AUTOSAR XML (schema 4-2-2)
standard types defined: boolean, float32, float64, sint16, sint32, sint64, sint8, uint16, uint32, uint64, uint8, void
package /BSW/ImplementationDataTypes
  6 x impl type:
    ConstVoidPtr: category=DATA_REFERENCE, sw-pointer-target-props={target-category=VALUE, base-type=void, sw-impl-policy=CONST}
    NvM_BlockIdType: category=VALUE, base-type=uint16
    NvM_BlockRequestType: compu {0x00=NVM_READ_BLOCK, 0x01=NVM_WRITE_BLOCK, 0x02=NVM_RESTORE_BLOCK_DEFAULTS, 0x03=NVM_ERASE_NV_BLOCK, 0x04=NVM_INVALIDATE_NV_BLOCK, 0x05=NVM_READ_ALL_BLOCK, 0x06=NVM_WRITE_ALL_BLOCK}, implementation-data-type=uint8
    NvM_InitBlockRequestType: compu {0x00=NVM_INIT_READ_BLOCK, 0x01=NVM_INIT_RESTORE_BLOCK_DEFAULTS, 0x02=NVM_INIT_READ_ALL_BLOCK, 0x03=NVM_INIT_FIRST_INIT_ALL}, implementation-data-type=uint8
    NvM_RequestResultType: compu {0x00=NVM_REQ_OK, 0x01=NVM_REQ_NOT_OK, 0x02=NVM_REQ_PENDING, 0x03=NVM_REQ_INTEGRITY_FAILED, 0x04=NVM_REQ_BLOCK_SKIPPED, 0x05=NVM_REQ_NV_INVALIDATED, 0x06=NVM_REQ_CANCELED, 0x08=NVM_REQ_RESTORED_DEFAULTS}, implementation-data-type=uint8
    VoidPtr: category=DATA_REFERENCE, sw-pointer-target-props={target-category=VALUE, base-type=void}
package /BSW/PortInterfaces
  client server interface NvM_ReadAll: service-kind=NON-VOLATILE-RAM-MANAGER
    operation ReadAll: possible-error=[NvM_ReadAll/E_NOT_OK, NvM_ReadAll/E_OK]
    error E_NOT_OK: error-code=1
    error E_OK: error-code=0
  client server interface NvM_WriteAll: service-kind=NON-VOLATILE-RAM-MANAGER
    operation WriteAll: possible-error=[NvM_WriteAll/E_NOT_OK, NvM_WriteAll/E_OK]
    error E_NOT_OK: error-code=1
    error E_OK: error-code=0
package /BSW/SWCs
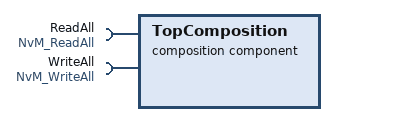
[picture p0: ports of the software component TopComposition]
  composition sw component type TopComposition
    require port ReadAll: required-interface=NvM_ReadAll
    require port WriteAll: required-interface=NvM_WriteAll
